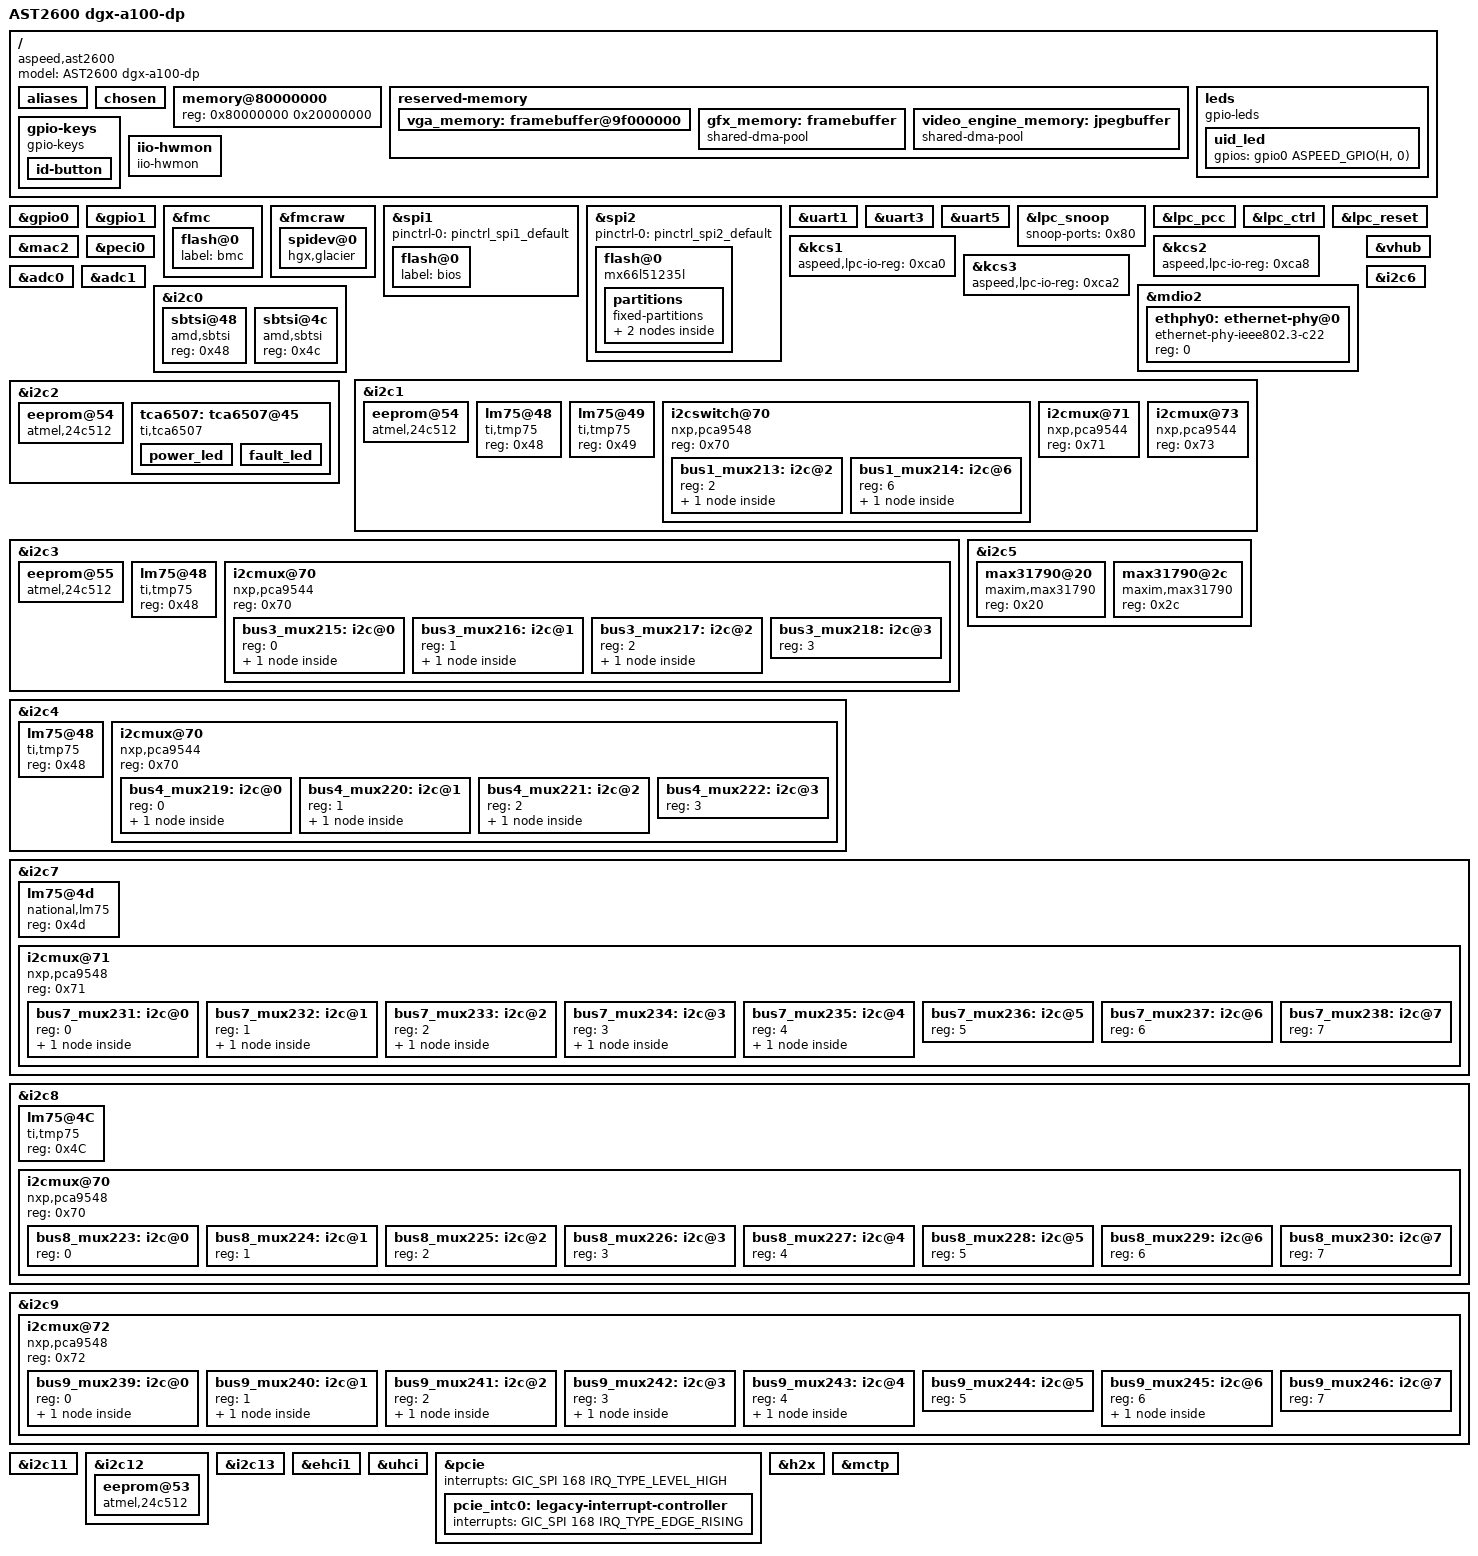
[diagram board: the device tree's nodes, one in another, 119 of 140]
// SPDX-License-Identifier: GPL-2.0+
/dts-v1/;

#include "aspeed-g6.dtsi"
#include "aspeed-g6-pinctrl.dtsi"
#include <dt-bindings/gpio/aspeed-gpio.h>
#include <dt-bindings/leds/common.h>

/ {
	model = "AST2600 dgx-a100-dp";
	compatible = "aspeed,ast2600";

	aliases {
		serial0 = &uart1;
		serial2 = &uart3;
		serial4 = &uart5;
		i2c213 = &bus1_mux213;
		i2c214 = &bus1_mux214;
		i2c215 = &bus3_mux215;
		i2c216 = &bus3_mux216;
		i2c217 = &bus3_mux217;
		i2c218 = &bus3_mux218;
		i2c219 = &bus4_mux219;
		i2c220 = &bus4_mux220;
		i2c221 = &bus4_mux221;
		i2c222 = &bus4_mux222;
		i2c223 = &bus8_mux223;
		i2c224 = &bus8_mux224;
		i2c225 = &bus8_mux225;
		i2c226 = &bus8_mux226;
		i2c227 = &bus8_mux227;
		i2c228 = &bus8_mux228;
		i2c229 = &bus8_mux229;
		i2c230 = &bus8_mux230;
		i2c231 = &bus7_mux231;
		i2c232 = &bus7_mux232;
		i2c233 = &bus7_mux233;
		i2c234 = &bus7_mux234;
		i2c235 = &bus7_mux235;
		i2c236 = &bus7_mux236;
		i2c237 = &bus7_mux237;
		i2c238 = &bus7_mux238;
		i2c239 = &bus9_mux239;
		i2c240 = &bus9_mux240;
		i2c241 = &bus9_mux241;
		i2c242 = &bus9_mux242;
		i2c243 = &bus9_mux243;
		i2c244 = &bus9_mux244;
		i2c245 = &bus9_mux245;
		i2c246 = &bus9_mux246;
	};

	chosen {
		stdout-path = &uart5;
		bootargs = "console=tty0 console=ttyS4,115200 earlyprintk";
	};

	memory@80000000 {
		reg = <0x80000000 0x20000000>;
	};

	reserved-memory {
		#address-cells = <1>;
		#size-cells = <1>;
		ranges;

		vga_memory: framebuffer@9f000000 {
			no-map;
			reg = <0x9f000000 0x01000000>; /* 16M */
		};

		gfx_memory: framebuffer {
			size = <0x01000000>;
			alignment = <0x01000000>;
			compatible = "shared-dma-pool";
			reusable;
		};

		video_engine_memory: jpegbuffer {
			size = <0x02000000>;	/* 32M */
			alignment = <0x01000000>;
			compatible = "shared-dma-pool";
			reusable;
		};
	};

	leds {
		compatible = "gpio-leds";
		uid_led {
			gpios = <&gpio0 ASPEED_GPIO(H, 0) GPIO_ACTIVE_HIGH>;
		};
	};

	gpio-keys {
		compatible = "gpio-keys";

		id-button {
			label = "id-button";
			gpios = <&gpio0 ASPEED_GPIO(H, 3) GPIO_ACTIVE_HIGH>;
			linux,code = <ASPEED_GPIO(H, 3)>;
		};
	};

	iio-hwmon {
		compatible = "iio-hwmon";
		io-channels = <&adc0 0>, <&adc0 1>, <&adc0 2>,
			<&adc0 3>, <&adc0 4>, <&adc0 5>,
			<&adc0 6>, <&adc0 7>, <&adc1 0>,
			<&adc1 1>, <&adc1 2>, <&adc1 3>,
			<&adc1 4>;
	};
};

&gpio0 {
	gpio-line-names =
	/*A0-A7*/       "","","","","","","","",
	/*B0-B7*/       "dimm_spd_sel","pwrgd_p3v3","bmc_rdv_set_ok","","","","","",
	/*C0-C7*/       "","","","","","","","",
	/*D0-D7*/       "","","","","","","","",
	/*E0-E7*/       "","","","","","bmc_bios_update_n","","",
	/*F0-F7*/       "","latch_gpu1_thermtrip_cpld_n","","bmc_cpld_boot_n","","","","",
	/*G0-G7*/       "","","","","","","","",
	/*H0-H7*/       "","","","","","","","",
	/*I0-I7*/       "","","bios_spi_cs_sel","bmc_ready","","","","",
	/*J0-J7*/       "","","","","","","","",
	/*K0-K7*/       "","","","","","","","",
	/*L0-L7*/       "","","","","","","","",
	/*M0-M7*/       "","","","","","","","",
	/*N0-N7*/       "","","","","","bat_det_en","","",
	/*O0-O7*/       "","","","","","","","psu_workok",
	/*P0-P7*/       "","","psu_alert_n","","","","","psu_detect_n",
	/*Q0-Q7*/       "","","","","","","","",
	/*R0-R7*/       "","","","","","","","",
	/*S0-S7*/       "","","","","","","","",
	/*T0-T7*/       "","","","","","","","",
	/*U0-U7*/       "","","","","","","","",
	/*V0-V7*/       "bmc_pwr_btn_n","","","","sys_pwrok","","","",
	/*W0-W7*/       "","","","","","","","",
	/*X0-X7*/       "","","","","","","","",
	/*Y0-Y7*/       "","","","","","","","",
	/*Z0-Z7*/       "","","","","","","","",
	/*AA0-AA7*/     "","","psu_ac_ok_all","","","","","",
	/*AB0-AB7*/     "","","","","","","","",
	/*AC0-AC7*/     "","","","","","","","";
};

&gpio1 {
        gpio-line-names =
        /*AA0-AA7*/     "","","","","","","","",
        /*AB0-AB7*/     "","","","","","","","",
        /*AC0-AC7*/     "","","","","","","","",
        /*AD0-AD7*/     "","","","","","","","",
        /*AE0-AE7*/     "","","","","","","","";
};

/* BMC Boot Flash */
&fmc {
	status = "okay";
	flash@0 {
        status = "okay";
        label = "bmc";
	#include "aspeed-bmc-nvidia-dgx-a100-flash-layout-64.dtsi"
    	};
};

&fmcraw {
    status = "okay";
    spidev@0 {
        compatible = "hgx,glacier";
        status = "okay";
    };
};

/* BIOS Flash */
&spi1 {
        status = "okay";
        pinctrl-names = "default";
        pinctrl-0 = <&pinctrl_spi1_default>;

        flash@0 {
                status = "okay";
                label = "bios";
        };
};

/* Config Flash */
&spi2 {
    status = "okay";
    pinctrl-names = "default";
    pinctrl-0 = <&pinctrl_spi2_default>;

    flash@0 {
        status = "okay";
        compatible = "mx66l51235l", "jedec,spi-nor";
        label = "config";
        spi-max-frequency = <50000000>;
        partitions {
            compatible = "fixed-partitions";
            #address-cells = <1>;
            #size-cells = <1>;

            u-boot-env@0 {
                reg = <0x0 0x40000>;
                label = "u-boot-env";
            };

            rwfs@20000 {
                reg = <0x40000 0x1000000>;
                label = "rwfs";
            };
        };
    };
};

&uart1 {
	// Rear COM1
	status = "okay";
	pinctrl-names = "default";
	pinctrl-0 = <&pinctrl_txd1_default
				 &pinctrl_rxd1_default>;
};

&uart3 {
	// CPU UART1 (FIXME: SOL??)
	status = "okay";
	pinctrl-names = "default";
	pinctrl-0 = <&pinctrl_txd3_default
				 &pinctrl_rxd3_default>;
};

&uart5 {
	// BMC Debug Console
	status = "okay";
};

&lpc_snoop {
	// SBIOS Post Code Port
	status = "okay";
	snoop-ports = <0x80>;
};

&lpc_pcc {
	rec-mode = <0x1>;
	port-addr = <0x80>;
	port-addr-hbits-select = <0x1>;
	port-addr-xbits = <0x3>;
	pattern-a-en;
	pattern-a = <0x41424344>;
	pattern-a-len = <0x4>;
	pattern-a-write = <0x1>;
	pattern-a-port = <0x80>;
	status = "okay";
	dma-mode = <0x1>;
};

&lpc_ctrl {
	status = "okay";
};

&lpc_reset {
	status = "okay";
};

&kcs1 {
	// KCS Channel 1
	status = "okay";
	aspeed,lpc-io-reg = <0xca0>;
};

&kcs2 {
	// KCS Channel 2
	status = "okay";
	aspeed,lpc-io-reg = <0xca8>;
};

&kcs3 {
	// KCS Channel 3
	status = "okay";
	aspeed,lpc-io-reg = <0xca2>;
};

&mdio2 {
        status = "okay";
        ethphy0: ethernet-phy@0 {
            compatible = "ethernet-phy-ieee802.3-c22";    
            reg = <0>;
       };
};

&mac2 {
	status = "okay";
	pinctrl-names = "default";
        phy-mode = "rgmii";
        max-speed = <1000>;
        phy-handle = <&ethphy0>;
	pinctrl-0 = <&pinctrl_rgmii3_default>;
};

&peci0{

        status = "okay";

};

/*
 * Enable port A as device (via the virtual hub) and port B as
 * host by default on the eval board. This can be easily changed
 * by replacing the override below with &ehci0 { ... } to enable
 * host on both ports.
 */
&vhub {
	status = "okay";
};

/*
&gfx {
	status = "okay";
	memory-region = <&gfx_memory>;
};

&video {
	status = "okay";
	memory-region = <&video_engine_memory>;
};
*/

&adc0 {
    status = "okay";
    pinctrl-names = "default";
    pinctrl-0 = <&pinctrl_adc0_default
            &pinctrl_adc1_default
            &pinctrl_adc2_default
            &pinctrl_adc3_default
            &pinctrl_adc4_default
            &pinctrl_adc5_default
            &pinctrl_adc6_default
            &pinctrl_adc7_default>;
};

&adc1 {
    status = "okay";
    pinctrl-names = "default";
    pinctrl-0 = <&pinctrl_adc8_default
            &pinctrl_adc9_default
            &pinctrl_adc10_default
            &pinctrl_adc11_default
            &pinctrl_adc12_default
            &pinctrl_adc13_default
            &pinctrl_adc14_default
            &pinctrl_adc15_default>;
};

&i2c0 {
    status = "okay";

    sbtsi@48 {
        compatible = "amd,sbtsi";
        reg = <0x48>;
    };

    sbtsi@4c {
        compatible = "amd,sbtsi";
        reg = <0x4c>;
    };
};

&i2c1 {
    status = "okay";

    // UFRU1
    eeprom@54 {
        compatible = "atmel,24c512";
        reg = <0x54>;
        pagesize = <128>;
        size = <65536>;
    };

    // Planar Temp Sensor U60
    lm75@48 {
        compatible = "ti,tmp75";
        reg = <0x48>;
    };

    // Planar Temp Sensor U139
    lm75@49 {
        compatible = "ti,tmp75";
        reg = <0x49>;
    };

    // i2c switch - U41
    i2cswitch@70 {
        compatible = "nxp,pca9548";
        #address-cells = <1>;
        #size-cells = <0>;
        reg = <0x70>;

        bus1_mux213: i2c@2 {
            #address-cells = <1>;
            #size-cells = <0>;
            reg = <2>;

             // TEMP_M.2_0
             lm75@4c {
                 compatible = "ti,tmp75";
                 reg = <0x4c>;
             };
        };

        // I2C_SW6_SDA
        bus1_mux214: i2c@6 {
            #address-cells = <1>;
            #size-cells = <0>;
            reg = <6>;

            // M.2 FRU
            eeprom@51 {
                compatible = "atmel,24c512";
                reg = <0x51>;
                pagesize = <128>;
                size = <65536>;
            };
        };
    };
    i2cmux@71 {
        compatible = "nxp,pca9544";
        reg = <0x71>;
    };
    i2cmux@73 {
        compatible = "nxp,pca9544";
        reg = <0x73>;
    };
};

&i2c2 {             
	status = "okay";

	// Midplane FRU
	eeprom@54 {
		compatible = "atmel,24c512";
		reg = <0x54>;
		pagesize = <128>;
		size = <65536>;
	};

	tca6507: tca6507@45 {
		compatible = "ti,tca6507";
		#address-cells = <1>;
		#size-cells = <0>;
		reg = <0x45>;

		gpio-controller;
		#gpio-cells = <2>;

		power_led {
			reg = <0x0>;
			color = <LED_COLOR_ID_GREEN>;
		};

		fault_led {
			reg = <0x1>;
			type = <LED_COLOR_ID_AMBER>;
		};
	};
};                  

// AST2500 i2c4
&i2c3 {
	status = "okay";

	// PDU FRU U7
	eeprom@55 {
		compatible = "atmel,24c512";
		reg = <0x55>;
		pagesize = <128>;
		size = <65536>;
	};

	// PDB Thermal 2 U2
	lm75@48 {
		compatible = "ti,tmp75";
		reg = <0x48>;
	};

    // 19115-1A PDB_20191018.pdf Page 3: SMB_PDB_2_* - I2C MUX U20
    /* Exclude in the device tree so MUX and PSU are accessible via SMBus
       (i.e. not owned by device tree binding drivers which makes device busy)*/
    i2cmux@70 {
        compatible = "nxp,pca9544";
        reg = <0x70>;

        // CNPSU1
        bus3_mux215: i2c@0 {
            reg = <0>;

            psu1@40 {
                compatible = "ericsson,bmr453";
                reg = <0x40>;
            };
        };
        // CNPSU2
        bus3_mux216: i2c@1 {
            reg = <1>;

            psu2@41 {
                compatible = "ericsson,bmr453";
                reg = <0x41>;
            };
        };
        // CNPSU3
        bus3_mux217: i2c@2 {
            reg = <2>;

            psu3@42 {
                compatible = "ericsson,bmr453";
                reg = <0x42>;
            };
        };

        bus3_mux218: i2c@3 {
            reg = <3>;
        };
    };
};

&i2c4 {             
    status = "okay";

    // PDB thermal 1 U1
    lm75@48 {                        
        compatible = "ti,tmp75";
        reg = <0x48>;                
    };                               

    // 19115-1A PDB_20191018.pdf Page 3: SMB_PDB_1_* - I2C MUX U19
    /* Exclude in the device tree so MUX and PSU are accessible via SMBus
       *i.e. not owned by device tree binding drivers which makes device busy)*/
    i2cmux@70 {
        compatible = "nxp,pca9544";
        reg = <0x70>;

       // CNPSU4
        bus4_mux219: i2c@0 {
            reg = <0>;

            psu4@40 {
                compatible = "ericsson,bmr453";
                reg = <0x40>;
            };
        };
        // CNPSU5
        bus4_mux220: i2c@1 {
            reg = <1>;

            psu5@41 {
                compatible = "ericsson,bmr453";
                reg = <0x41>;
            };
        };
        // CNPSU6
        bus4_mux221: i2c@2 {
            reg = <2>;

            psu6@42 {
                compatible = "ericsson,bmr453";
                reg = <0x42>;
            };
        };

        bus4_mux222: i2c@3 {
            reg = <3>;
        };
    };
};                  

&i2c5 {             
    status = "okay";

    // MB Fan U1
    max31790@20 {
        compatible = "maxim,max31790";
        reg = <0x20>;
        #address-cells = <1>;
        #size-cells = <0>;
    };

    // GB1 Fan
    max31790@2c {
        compatible = "maxim,max31790";
        reg = <0x2c>;
    };
};                  

&i2c6 {             
    status = "okay";
};                  

&i2c7 {
	status = "okay";

	lm75@4d {
		compatible = "national,lm75";
		reg = <0x4d>;
	};

    i2cmux@71 {
        compatible = "nxp,pca9548";
        reg = <0x71>;
        bus7_mux231: i2c@0 {
            reg = <0>;
            tmp421@1f {
                compatible = "ti,tmp421";
                reg = <0x1f>;
            };
        };
        bus7_mux232: i2c@1 {
            reg = <1>;
            tmp421@1f {
                compatible = "ti,tmp421";
                reg = <0x1f>;
            };
        };
        bus7_mux233: i2c@2 {
            reg = <2>;
            tmp421@1f {
                compatible = "ti,tmp421";
                reg = <0x1f>;
            };
        };
        bus7_mux234: i2c@3 {
            reg = <3>;
            tmp421@1f {
                compatible = "ti,tmp421";
                reg = <0x1f>;
            };
        };
        bus7_mux235: i2c@4 {
            reg = <4>;
            // IOE board 0 FRU
            eeprom@51 {
                compatible = "atmel,24c512";
                reg = <0x51>;
                pagesize = <128>;
                size = <65536>;
            };
        };
        bus7_mux236: i2c@5 {
            reg = <5>;
        };
        bus7_mux237: i2c@6 {
            reg = <6>;
        };
        bus7_mux238: i2c@7 {
            reg = <7>;
        };
    };
};

&i2c8 {
    status = "okay";

    // Midplane thermal
    lm75@4C {
        compatible = "ti,tmp75";
        reg = <0x4C>;
    };

    i2cmux@70 {
        compatible = "nxp,pca9548";
        reg = <0x70>;

        // NVMe0
        bus8_mux223: i2c@0 {
            reg = <0>;
        };
        // NVMe1
        bus8_mux224: i2c@1 {
            reg = <1>;
        };
        // NVMe2
        bus8_mux225: i2c@2 {
            reg = <2>;
        };
        // NVMe3
        bus8_mux226: i2c@3 {
            reg = <3>;
        };
        // NVMe4
        bus8_mux227: i2c@4 {
            reg = <4>;
        };
        // NVMe5
        bus8_mux228: i2c@5 {
            reg = <5>;
        };
        // NVMe6
        bus8_mux229: i2c@6 {
            reg = <6>;
        };
        // NVMe7
        bus8_mux230: i2c@7 {
            reg = <7>;
        };
    };
};

&i2c9 {             
    status = "okay";

    i2cmux@72 {
        compatible = "nxp,pca9548";
        reg = <0x72>;
         bus9_mux239: i2c@0 {
            reg = <0>;
            tmp421@1f {
                compatible = "ti,tmp421";
                reg = <0x1f>;
            };
        };
        bus9_mux240: i2c@1 {
            reg = <1>;
            tmp421@1f {
                compatible = "ti,tmp421";
                reg = <0x1f>;
            };
        };
        bus9_mux241: i2c@2 {
            reg = <2>;
            tmp421@1f {
                compatible = "ti,tmp421";
                reg = <0x1f>;
            };
        };
        bus9_mux242: i2c@3 {
            reg = <3>;
            tmp421@1f {
                compatible = "ti,tmp421";
                reg = <0x1f>;
            };
        };
        bus9_mux243: i2c@4 {
            reg = <4>;
            // IOE board 1 FRU
            eeprom@52 {
                compatible = "atmel,24c512";
                reg = <0x52>;
                pagesize = <128>;
                size = <65536>;
            };
        };
        bus9_mux244: i2c@5 {
            reg = <5>;
        };
        bus9_mux245: i2c@6 {
             reg = <6>;
            // SW Board  FRU
            eeprom@57 {
                compatible = "atmel,24c512";
                reg = <0x57>;
                pagesize = <128>;
                size = <65536>;
            };
        };
        bus9_mux246: i2c@7 {
            reg = <7>;
        };
    };
};

/* GPU 1 */
&i2c11 {
	status = "okay";
};

/* GPU 2 */
&i2c12 {
        status = "okay";

    // GPU Baseboard FRU
    eeprom@53 {
        compatible = "atmel,24c512";
        reg = <0x53>;
        pagesize = <128>;
        size = <65536>;
    };
};


/* CEC */
&i2c13 {
	status = "okay";
};

&ehci1 {
   status = "okay";
};

// USB 1.0
&uhci {
   status = "okay";
};


// PCIe RC
&pcie {
        status = "okay";

        interrupts = <GIC_SPI 168 IRQ_TYPE_LEVEL_HIGH>;

        pcie_intc0: legacy-interrupt-controller {
                interrupts = <GIC_SPI 168 IRQ_TYPE_EDGE_RISING>;
        };
};
// Bridge between AHB bus and PCIe RC.
&h2x {
        status = "okay";
};

&mctp {
	status = "okay";
};
